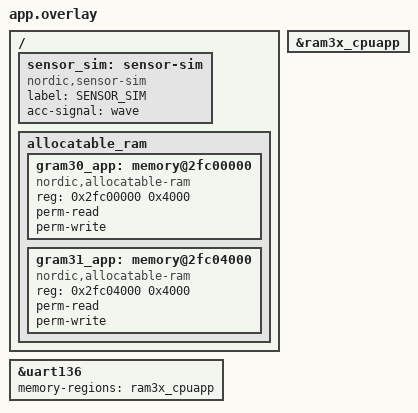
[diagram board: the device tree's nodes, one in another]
/*
 * Copyright (c) 2022 Nordic Semiconductor ASA
 *
 * SPDX-License-Identifier: LicenseRef-Nordic-5-Clause
 */

/ {
	sensor_sim: sensor-sim {
		compatible = "nordic,sensor-sim";
		label = "SENSOR_SIM";
		acc-signal = "wave";
	};

	allocatable_ram {
		#address-cells = <1>;
		#size-cells = <1>;

		/* Configuration required by nrf-regtool v2. */
		gram30_app: memory@2fc00000 {
			compatible = "nordic,allocatable-ram";
			reg = <0x2fc00000 0x4000>;
			perm-read;
			perm-write;
		};

		/* Configuration required by nrf-regtool v2. */
		gram31_app: memory@2fc04000 {
			compatible = "nordic,allocatable-ram";
			reg = <0x2fc04000 0x4000>;
			perm-read;
			perm-write;
		};
	};
};

&ram3x_cpuapp {
	status = "okay";
};

&uart136 {
	status = "okay";
	memory-regions = <&ram3x_cpuapp>;
};
